AUTOSAR XML (schema 00052)
package /Components
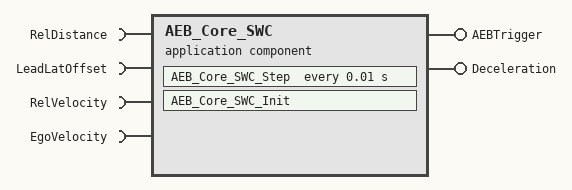
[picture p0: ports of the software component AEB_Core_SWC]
  application sw component type AEB_Core_SWC
    4 x require port:
      RelDistance: nonqueued-receiver-com-spec{data-element=RelDistance, init-value=0}, required-interface=RelDistance
      LeadLatOffset: nonqueued-receiver-com-spec{data-element=LeadLatOffset, init-value=0}, required-interface=LeadLatOffset
      RelVelocity: nonqueued-receiver-com-spec{data-element=RelVelocity, init-value=0}, required-interface=RelVelocity
      EgoVelocity: nonqueued-receiver-com-spec{data-element=EgoVelocity, init-value=0}, required-interface=EgoVelocity
    provide port AEBTrigger: nonqueued-sender-com-spec{data-element=AEBTrigger, init-value=0}, provided-interface=AEBTrigger
    provide port Deceleration: nonqueued-sender-com-spec{data-element=Deceleration, init-value=0}, provided-interface=Deceleration
    behavior AEB_Core_SWC_IB: handle-termination-and-restart=NO-SUPPORT
      timing event Event_AEB_Core_SWC_Step: start-on-event=AEB_Core_SWC_Step, period=0.01
      runnable AEB_Core_SWC_Init
      runnable AEB_Core_SWC_Step
        data-read-access:
          4 x access:
            IN_EgoVelocity_EgoVelocity: accessed-variable=EgoVelocity.EgoVelocity
            IN_LeadLatOffset_LeadLatOffset: accessed-variable=LeadLatOffset.LeadLatOffset
            IN_RelDistance_RelDistance: accessed-variable=RelDistance.RelDistance
            IN_RelVelocity_RelVelocity: accessed-variable=RelVelocity.RelVelocity
        data-write-access:
          access OUT_AEBTrigger_AEBTrigger: accessed-variable=AEBTrigger.AEBTrigger
          access OUT_Deceleration_Deceleration: accessed-variable=Deceleration.Deceleration
